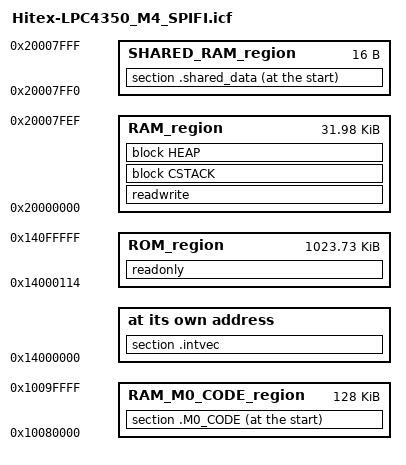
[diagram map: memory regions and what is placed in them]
/*###ICF### Section handled by ICF editor, don't touch! ****/
/*-Editor annotation file-*/
/* IcfEditorFile="$TOOLKIT_DIR$\config\ide\IcfEditor\cortex_v1_0.xml" */
/*-Specials-*/
define symbol __ICFEDIT_intvec_start__ = 0x14000000;
/*-Memory Regions-*/
define symbol __ICFEDIT_region_ROM_start__ = 0x14000114;
define symbol __ICFEDIT_region_ROM_end__   = 0x140FFFFF;
define symbol __ICFEDIT_region_RAM_start__ = 0x20000000;
define symbol __ICFEDIT_region_RAM_end__   = 0x20007FEF;
/*-Sizes-*/
define symbol __ICFEDIT_size_cstack__ = 0x400;
define symbol __ICFEDIT_size_heap__   = 0x200;
/**** End of ICF editor section. ###ICF###*/

define symbol RAM_M0_CODE_start__ = 0x10080000;
define symbol RAM_M0_CODE_end__   = 0x1009FFFF;

define symbol SHARED_RAM_start__ = 0x20007FF0;
define symbol SHARED_RAM_end__   = 0x20007FFF;

/* define symbol __CRP_start__   = 0x000002FC; */
/* define symbol __CRP_end__     = 0x000002FF; */

define memory mem with size = 4G;
define region ROM_region   = mem:[from __ICFEDIT_region_ROM_start__   to __ICFEDIT_region_ROM_end__];
define region RAM_region   = mem:[from __ICFEDIT_region_RAM_start__   to __ICFEDIT_region_RAM_end__];
define region RAM_M0_CODE_region   = mem:[from RAM_M0_CODE_start__   to RAM_M0_CODE_end__];
define region SHARED_RAM_region = mem:[from SHARED_RAM_start__   to SHARED_RAM_end__];
/* define region CRP_region   = mem:[from  __CRP_start__ to __CRP_end__]; */

define block CSTACK    with alignment = 8, size = __ICFEDIT_size_cstack__   { };
define block HEAP      with alignment = 8, size = __ICFEDIT_size_heap__     { };

initialize by copy { readwrite };

initialize by copy with packing = zeros { section .M0_CODE };

do not initialize  { section .noinit };

place at address mem:__ICFEDIT_intvec_start__ { section .intvec };

place at start of ROM_region { block StartupCode with fixed order { ro object cstartup_M.o, ro object init.o, ro object cmain.o } };

place in ROM_region     { readonly };
place in RAM_region     { readwrite,
                          block CSTACK, block HEAP };

place at start of RAM_M0_CODE_region { section .M0_CODE };

place at start of SHARED_RAM_region { section .shared_data };

/* place in CRP_region  { section .crp}; */
